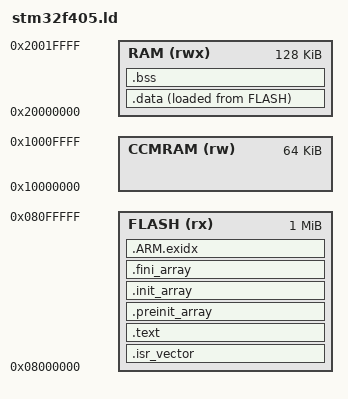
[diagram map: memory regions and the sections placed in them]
/* Minimal STM32F405RG linker script.
 * WARNING: the CCM RAM is NOT DMA-capable - DMA buffers (DShot, SPI) must be
 * placed explicitly outside CCM. */

ENTRY(Reset_Handler)

MEMORY
{
  FLASH  (rx)  : ORIGIN = 0x08000000, LENGTH = 1024K
  RAM    (rwx) : ORIGIN = 0x20000000, LENGTH = 128K
  CCMRAM (rw)  : ORIGIN = 0x10000000, LENGTH = 64K
}

_estack = ORIGIN(RAM) + LENGTH(RAM);

SECTIONS
{
  .isr_vector :
  {
    KEEP(*(.isr_vector))
  } > FLASH

  .text :
  {
    *(.text*)
    *(.rodata*)
    . = ALIGN(4);
  } > FLASH

  /* C++ init arrays (walked by __libc_init_array). */
  .preinit_array :
  {
    PROVIDE_HIDDEN(__preinit_array_start = .);
    KEEP(*(.preinit_array*))
    PROVIDE_HIDDEN(__preinit_array_end = .);
  } > FLASH

  .init_array :
  {
    PROVIDE_HIDDEN(__init_array_start = .);
    KEEP(*(SORT(.init_array.*)))
    KEEP(*(.init_array*))
    PROVIDE_HIDDEN(__init_array_end = .);
  } > FLASH

  .fini_array :
  {
    PROVIDE_HIDDEN(__fini_array_start = .);
    KEEP(*(SORT(.fini_array.*)))
    KEEP(*(.fini_array*))
    PROVIDE_HIDDEN(__fini_array_end = .);
  } > FLASH

  .ARM.exidx :
  {
    __exidx_start = .;
    *(.ARM.exidx* .gnu.linkonce.armexidx.*)
    __exidx_end = .;
  } > FLASH

  _sidata = LOADADDR(.data);

  .data :
  {
    . = ALIGN(4);
    _sdata = .;
    *(.data*)
    . = ALIGN(4);
    _edata = .;
  } > RAM AT> FLASH

  .bss :
  {
    . = ALIGN(4);
    _sbss = .;
    *(.bss*)
    *(COMMON)
    . = ALIGN(4);
    _ebss = .;
  } > RAM

  /* Heap for _sbrk (newlib nosys). */
  PROVIDE(end = .);
  PROVIDE(_end = .);
}
